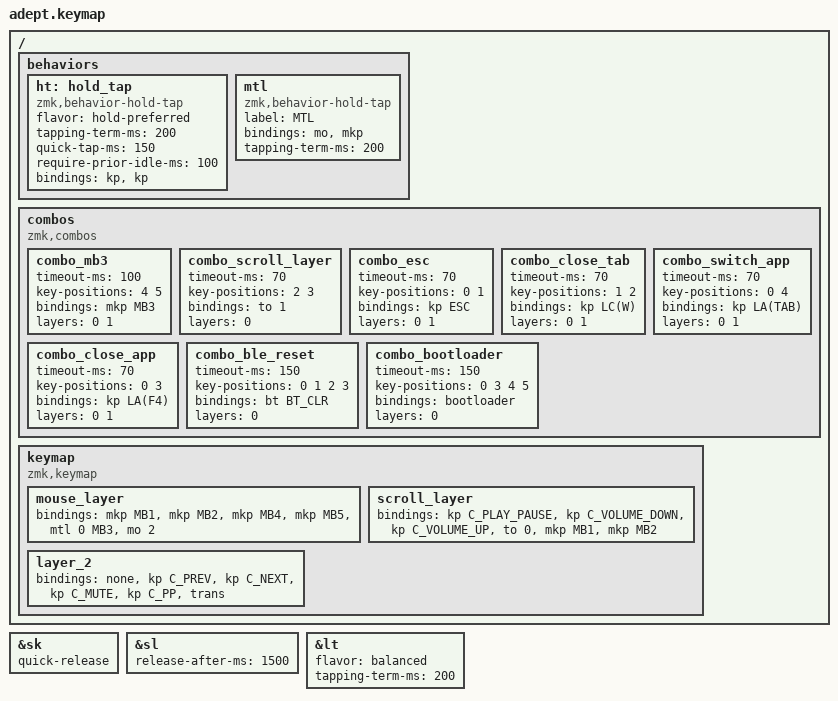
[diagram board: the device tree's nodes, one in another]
/*
    No chosen zmk,matrix-transform here if using ZMK stuidio.
    https://zmk.dev/docs/features/studio#adding-zmk-studio-support-to-a-keyboard
*/

#include <input/processors.dtsi>
#include <dt-bindings/zmk/mouse.h>
#include <dt-bindings/zmk/behaviors.h>
#include <dt-bindings/zmk/input_transform.h>
#include <zephyr/dt-bindings/input/input-event-codes.h>
#include <behaviors.dtsi>
#include <dt-bindings/zmk/bt.h>
#include <dt-bindings/zmk/keys.h>
#include <dt-bindings/zmk/pointing.h>

// keep all behavior settings for zmk studio

#define ZMK_BEHAVIORS_OMIT_KT

&sk { quick-release; };

&sl { release-after-ms = <1500>; };

&lt {
    flavor = "balanced";
    tapping-term-ms = <200>;
};

/ {
    behaviors {
        ht: hold_tap {
            compatible = "zmk,behavior-hold-tap";
            #binding-cells = <2>;
            flavor = "hold-preferred";
            tapping-term-ms = <200>;
            quick-tap-ms = <150>;
            require-prior-idle-ms = <100>;
            bindings = <&kp>, <&kp>;
        };

        mtl: mtl {
            compatible = "zmk,behavior-hold-tap";
            label = "MTL";
            bindings = <&mo>, <&mkp>;

            #binding-cells = <2>;
            tapping-term-ms = <200>;
        };
    };

    combos {
        compatible = "zmk,combos";

        combo_mb3 {
            timeout-ms = <100>;
            key-positions = <4 5>;
            bindings = <&mkp MB3>;
            layers = <0 1>;
        };

        combo_scroll_layer {
            timeout-ms = <70>;
            key-positions = <2 3>;
            bindings = <&to 1>;
            layers = <0>;
        };

        combo_esc {
            timeout-ms = <70>;
            key-positions = <0 1>;
            bindings = <&kp ESC>;
            layers = <0 1>;
        };

        combo_close_tab {
            timeout-ms = <70>;
            key-positions = <1 2>;
            bindings = <&kp LC(W)>;
            layers = <0 1>;
        };

        combo_switch_app {
            timeout-ms = <70>;
            key-positions = <0 4>;
            bindings = <&kp LA(TAB)>;
            layers = <0 1>;
        };

        combo_close_app {
            timeout-ms = <70>;
            key-positions = <0 3>;
            bindings = <&kp LA(F4)>;
            layers = <0 1>;
        };

        combo_ble_reset {
            timeout-ms = <150>;
            key-positions = <0 1 2 3>;
            bindings = <&bt BT_CLR>;
            layers = <0>;
        };

        combo_bootloader {
            timeout-ms = <150>;
            key-positions = <0 3 4 5>;
            bindings = <&bootloader>;
            layers = <0>;
        };
    };

    keymap {
        compatible = "zmk,keymap";

        mouse_layer {
            bindings = <
&mkp MB1  &mkp MB2  &mkp MB4  &mkp MB5  &mtl 0 MB3  &mo 2
            >;
        };

        scroll_layer {
            bindings = <
&kp C_PLAY_PAUSE  &kp C_VOLUME_DOWN  &kp C_VOLUME_UP  &to 0  &mkp MB1  &mkp MB2
            >;
        };

        layer_2 {
            bindings = <
&none  &kp C_PREV  &kp C_NEXT  &kp C_MUTE  &kp C_PP  &trans
            >;
        };
    };
};
